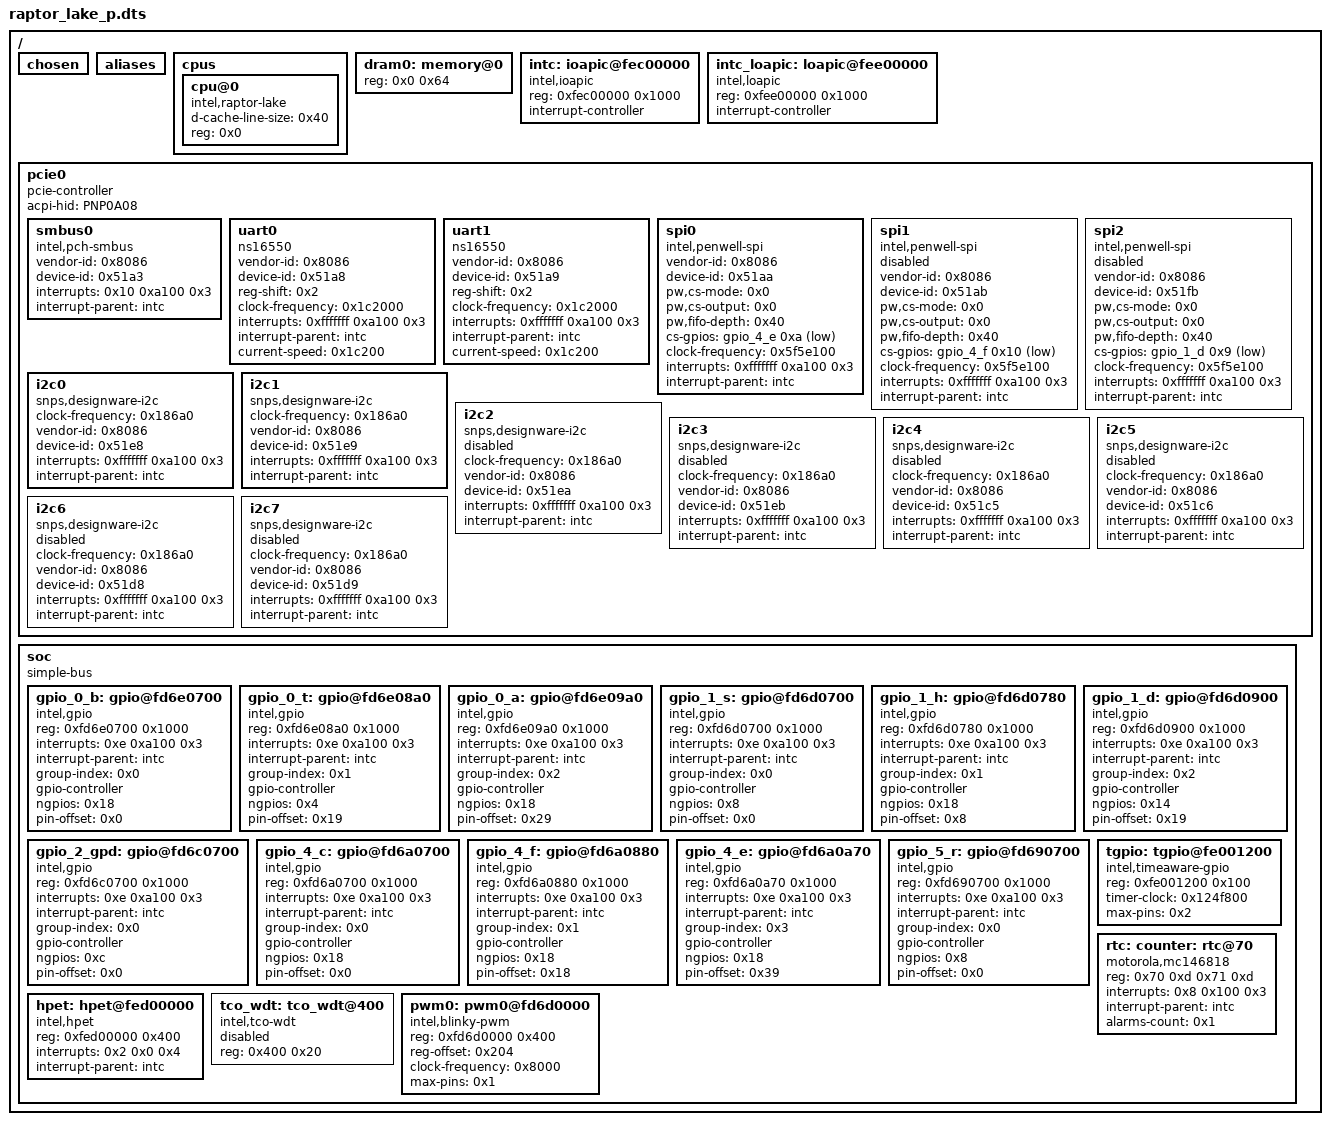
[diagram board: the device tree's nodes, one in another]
/dts-v1/;

/ {
	#address-cells = < 0x1 >;
	#size-cells = < 0x1 >;
	chosen {
	};
	aliases {
	};
	cpus {
		#address-cells = < 0x1 >;
		#size-cells = < 0x0 >;
		cpu@0 {
			compatible = "intel,raptor-lake";
			device_type = "cpu";
			d-cache-line-size = < 0x40 >;
			reg = < 0x0 >;
		};
	};
	dram0: memory@0 {
		device_type = "memory";
		reg = < 0x0 0x64 >;
	};
	intc: ioapic@fec00000 {
		compatible = "intel,ioapic";
		reg = < 0xfec00000 0x1000 >;
		interrupt-controller;
		#interrupt-cells = < 0x3 >;
		phandle = < 0x1 >;
	};
	intc_loapic: loapic@fee00000 {
		compatible = "intel,loapic";
		reg = < 0xfee00000 0x1000 >;
		interrupt-controller;
		#interrupt-cells = < 0x3 >;
		#address-cells = < 0x1 >;
	};
	pcie0: pcie0 {
		compatible = "pcie-controller";
		#address-cells = < 0x1 >;
		#size-cells = < 0x1 >;
		acpi-hid = "PNP0A08";
		ranges;
		smbus0: smbus0 {
			compatible = "intel,pch-smbus";
			#address-cells = < 0x1 >;
			#size-cells = < 0x0 >;
			vendor-id = < 0x8086 >;
			device-id = < 0x51a3 >;
			interrupts = < 0x10 0xa100 0x3 >;
			interrupt-parent = < &intc >;
			status = "okay";
		};
		uart0: uart0 {
			compatible = "ns16550";
			vendor-id = < 0x8086 >;
			device-id = < 0x51a8 >;
			reg-shift = < 0x2 >;
			clock-frequency = < 0x1c2000 >;
			interrupts = < 0xfffffff 0xa100 0x3 >;
			interrupt-parent = < &intc >;
			current-speed = < 0x1c200 >;
			status = "okay";
		};
		uart1: uart1 {
			compatible = "ns16550";
			vendor-id = < 0x8086 >;
			device-id = < 0x51a9 >;
			reg-shift = < 0x2 >;
			clock-frequency = < 0x1c2000 >;
			interrupts = < 0xfffffff 0xa100 0x3 >;
			interrupt-parent = < &intc >;
			current-speed = < 0x1c200 >;
			status = "okay";
		};
		spi0: spi0 {
			compatible = "intel,penwell-spi";
			#address-cells = < 0x1 >;
			#size-cells = < 0x0 >;
			vendor-id = < 0x8086 >;
			device-id = < 0x51aa >;
			pw,cs-mode = < 0x0 >;
			pw,cs-output = < 0x0 >;
			pw,fifo-depth = < 0x40 >;
			cs-gpios = < &gpio_4_e 0xa 0x1 >;
			clock-frequency = < 0x5f5e100 >;
			interrupts = < 0xfffffff 0xa100 0x3 >;
			interrupt-parent = < &intc >;
			status = "okay";
		};
		spi1: spi1 {
			compatible = "intel,penwell-spi";
			#address-cells = < 0x1 >;
			#size-cells = < 0x0 >;
			vendor-id = < 0x8086 >;
			device-id = < 0x51ab >;
			pw,cs-mode = < 0x0 >;
			pw,cs-output = < 0x0 >;
			pw,fifo-depth = < 0x40 >;
			cs-gpios = < &gpio_4_f 0x10 0x1 >;
			clock-frequency = < 0x5f5e100 >;
			interrupts = < 0xfffffff 0xa100 0x3 >;
			interrupt-parent = < &intc >;
			status = "disabled";
		};
		spi2: spi2 {
			compatible = "intel,penwell-spi";
			#address-cells = < 0x1 >;
			#size-cells = < 0x0 >;
			vendor-id = < 0x8086 >;
			device-id = < 0x51fb >;
			pw,cs-mode = < 0x0 >;
			pw,cs-output = < 0x0 >;
			pw,fifo-depth = < 0x40 >;
			cs-gpios = < &gpio_1_d 0x9 0x1 >;
			clock-frequency = < 0x5f5e100 >;
			interrupts = < 0xfffffff 0xa100 0x3 >;
			interrupt-parent = < &intc >;
			status = "disabled";
		};
		i2c0: i2c0 {
			compatible = "snps,designware-i2c";
			#address-cells = < 0x1 >;
			#size-cells = < 0x0 >;
			clock-frequency = < 0x186a0 >;
			vendor-id = < 0x8086 >;
			device-id = < 0x51e8 >;
			interrupts = < 0xfffffff 0xa100 0x3 >;
			interrupt-parent = < &intc >;
			status = "okay";
		};
		i2c1: i2c1 {
			compatible = "snps,designware-i2c";
			#address-cells = < 0x1 >;
			#size-cells = < 0x0 >;
			clock-frequency = < 0x186a0 >;
			vendor-id = < 0x8086 >;
			device-id = < 0x51e9 >;
			interrupts = < 0xfffffff 0xa100 0x3 >;
			interrupt-parent = < &intc >;
			status = "okay";
		};
		i2c2: i2c2 {
			compatible = "snps,designware-i2c";
			#address-cells = < 0x1 >;
			#size-cells = < 0x0 >;
			clock-frequency = < 0x186a0 >;
			vendor-id = < 0x8086 >;
			device-id = < 0x51ea >;
			interrupts = < 0xfffffff 0xa100 0x3 >;
			interrupt-parent = < &intc >;
			status = "disabled";
		};
		i2c3: i2c3 {
			compatible = "snps,designware-i2c";
			#address-cells = < 0x1 >;
			#size-cells = < 0x0 >;
			clock-frequency = < 0x186a0 >;
			vendor-id = < 0x8086 >;
			device-id = < 0x51eb >;
			interrupts = < 0xfffffff 0xa100 0x3 >;
			interrupt-parent = < &intc >;
			status = "disabled";
		};
		i2c4: i2c4 {
			compatible = "snps,designware-i2c";
			#address-cells = < 0x1 >;
			#size-cells = < 0x0 >;
			clock-frequency = < 0x186a0 >;
			vendor-id = < 0x8086 >;
			device-id = < 0x51c5 >;
			interrupts = < 0xfffffff 0xa100 0x3 >;
			interrupt-parent = < &intc >;
			status = "disabled";
		};
		i2c5: i2c5 {
			compatible = "snps,designware-i2c";
			#address-cells = < 0x1 >;
			#size-cells = < 0x0 >;
			clock-frequency = < 0x186a0 >;
			vendor-id = < 0x8086 >;
			device-id = < 0x51c6 >;
			interrupts = < 0xfffffff 0xa100 0x3 >;
			interrupt-parent = < &intc >;
			status = "disabled";
		};
		i2c6: i2c6 {
			compatible = "snps,designware-i2c";
			#address-cells = < 0x1 >;
			#size-cells = < 0x0 >;
			clock-frequency = < 0x186a0 >;
			vendor-id = < 0x8086 >;
			device-id = < 0x51d8 >;
			interrupts = < 0xfffffff 0xa100 0x3 >;
			interrupt-parent = < &intc >;
			status = "disabled";
		};
		i2c7: i2c7 {
			compatible = "snps,designware-i2c";
			#address-cells = < 0x1 >;
			#size-cells = < 0x0 >;
			clock-frequency = < 0x186a0 >;
			vendor-id = < 0x8086 >;
			device-id = < 0x51d9 >;
			interrupts = < 0xfffffff 0xa100 0x3 >;
			interrupt-parent = < &intc >;
			status = "disabled";
		};
	};
	soc {
		compatible = "simple-bus";
		#address-cells = < 0x1 >;
		#size-cells = < 0x1 >;
		ranges;
		gpio_0_b: gpio@fd6e0700 {
			compatible = "intel,gpio";
			reg = < 0xfd6e0700 0x1000 >;
			interrupts = < 0xe 0xa100 0x3 >;
			interrupt-parent = < &intc >;
			group-index = < 0x0 >;
			gpio-controller;
			#gpio-cells = < 0x2 >;
			ngpios = < 0x18 >;
			pin-offset = < 0x0 >;
			status = "okay";
		};
		gpio_0_t: gpio@fd6e08a0 {
			compatible = "intel,gpio";
			reg = < 0xfd6e08a0 0x1000 >;
			interrupts = < 0xe 0xa100 0x3 >;
			interrupt-parent = < &intc >;
			group-index = < 0x1 >;
			gpio-controller;
			#gpio-cells = < 0x2 >;
			ngpios = < 0x4 >;
			pin-offset = < 0x19 >;
			status = "okay";
		};
		gpio_0_a: gpio@fd6e09a0 {
			compatible = "intel,gpio";
			reg = < 0xfd6e09a0 0x1000 >;
			interrupts = < 0xe 0xa100 0x3 >;
			interrupt-parent = < &intc >;
			group-index = < 0x2 >;
			gpio-controller;
			#gpio-cells = < 0x2 >;
			ngpios = < 0x18 >;
			pin-offset = < 0x29 >;
			status = "okay";
		};
		gpio_1_s: gpio@fd6d0700 {
			compatible = "intel,gpio";
			reg = < 0xfd6d0700 0x1000 >;
			interrupts = < 0xe 0xa100 0x3 >;
			interrupt-parent = < &intc >;
			group-index = < 0x0 >;
			gpio-controller;
			#gpio-cells = < 0x2 >;
			ngpios = < 0x8 >;
			pin-offset = < 0x0 >;
			status = "okay";
		};
		gpio_1_h: gpio@fd6d0780 {
			compatible = "intel,gpio";
			reg = < 0xfd6d0780 0x1000 >;
			interrupts = < 0xe 0xa100 0x3 >;
			interrupt-parent = < &intc >;
			group-index = < 0x1 >;
			gpio-controller;
			#gpio-cells = < 0x2 >;
			ngpios = < 0x18 >;
			pin-offset = < 0x8 >;
			status = "okay";
		};
		gpio_1_d: gpio@fd6d0900 {
			compatible = "intel,gpio";
			reg = < 0xfd6d0900 0x1000 >;
			interrupts = < 0xe 0xa100 0x3 >;
			interrupt-parent = < &intc >;
			group-index = < 0x2 >;
			gpio-controller;
			#gpio-cells = < 0x2 >;
			ngpios = < 0x14 >;
			pin-offset = < 0x19 >;
			status = "okay";
			phandle = < 0x4 >;
		};
		gpio_2_gpd: gpio@fd6c0700 {
			compatible = "intel,gpio";
			reg = < 0xfd6c0700 0x1000 >;
			interrupts = < 0xe 0xa100 0x3 >;
			interrupt-parent = < &intc >;
			group-index = < 0x0 >;
			gpio-controller;
			#gpio-cells = < 0x2 >;
			ngpios = < 0xc >;
			pin-offset = < 0x0 >;
			status = "okay";
		};
		gpio_4_c: gpio@fd6a0700 {
			compatible = "intel,gpio";
			reg = < 0xfd6a0700 0x1000 >;
			interrupts = < 0xe 0xa100 0x3 >;
			interrupt-parent = < &intc >;
			group-index = < 0x0 >;
			gpio-controller;
			#gpio-cells = < 0x2 >;
			ngpios = < 0x18 >;
			pin-offset = < 0x0 >;
			status = "okay";
		};
		gpio_4_f: gpio@fd6a0880 {
			compatible = "intel,gpio";
			reg = < 0xfd6a0880 0x1000 >;
			interrupts = < 0xe 0xa100 0x3 >;
			interrupt-parent = < &intc >;
			group-index = < 0x1 >;
			gpio-controller;
			#gpio-cells = < 0x2 >;
			ngpios = < 0x18 >;
			pin-offset = < 0x18 >;
			status = "okay";
			phandle = < 0x3 >;
		};
		gpio_4_e: gpio@fd6a0a70 {
			compatible = "intel,gpio";
			reg = < 0xfd6a0a70 0x1000 >;
			interrupts = < 0xe 0xa100 0x3 >;
			interrupt-parent = < &intc >;
			group-index = < 0x3 >;
			gpio-controller;
			#gpio-cells = < 0x2 >;
			ngpios = < 0x18 >;
			pin-offset = < 0x39 >;
			status = "okay";
			phandle = < 0x2 >;
		};
		gpio_5_r: gpio@fd690700 {
			compatible = "intel,gpio";
			reg = < 0xfd690700 0x1000 >;
			interrupts = < 0xe 0xa100 0x3 >;
			interrupt-parent = < &intc >;
			group-index = < 0x0 >;
			gpio-controller;
			#gpio-cells = < 0x2 >;
			ngpios = < 0x8 >;
			pin-offset = < 0x0 >;
			status = "okay";
		};
		tgpio: tgpio@fe001200 {
			compatible = "intel,timeaware-gpio";
			reg = < 0xfe001200 0x100 >;
			timer-clock = < 0x124f800 >;
			max-pins = < 0x2 >;
			status = "okay";
		};
		rtc: counter: rtc@70 {
			compatible = "motorola,mc146818";
			reg = < 0x70 0xd 0x71 0xd >;
			interrupts = < 0x8 0x100 0x3 >;
			interrupt-parent = < &intc >;
			alarms-count = < 0x1 >;
			status = "okay";
		};
		hpet: hpet@fed00000 {
			compatible = "intel,hpet";
			reg = < 0xfed00000 0x400 >;
			interrupts = < 0x2 0x0 0x4 >;
			interrupt-parent = < &intc >;
			status = "okay";
		};
		tco_wdt: tco_wdt@400 {
			compatible = "intel,tco-wdt";
			reg = < 0x400 0x20 >;
			status = "disabled";
		};
		pwm0: pwm0@fd6d0000 {
			compatible = "intel,blinky-pwm";
			reg = < 0xfd6d0000 0x400 >;
			reg-offset = < 0x204 >;
			clock-frequency = < 0x8000 >;
			max-pins = < 0x1 >;
			#pwm-cells = < 0x2 >;
			status = "okay";
		};
	};
};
